# STM32H563 register map
File version: 0.4
CPU: CM33 r0p0, little endian, MPU, FPU, 4 interrupt priority bits
Registers are 32-bit, read-write, reset 0x0 unless marked. A register's access mark holds for its fields unless they carry their own. Offsets are from the block's base; [hi:lo] are bit positions; lines under a group give offsets from that group; {n}, {i} and the like mark numbered series; 'fields as' and 'values as' point back to an identical list.

## FLASH — FLASH address block description
Base 0x40022000
Same registers: SEC_FLASH 0x50022000
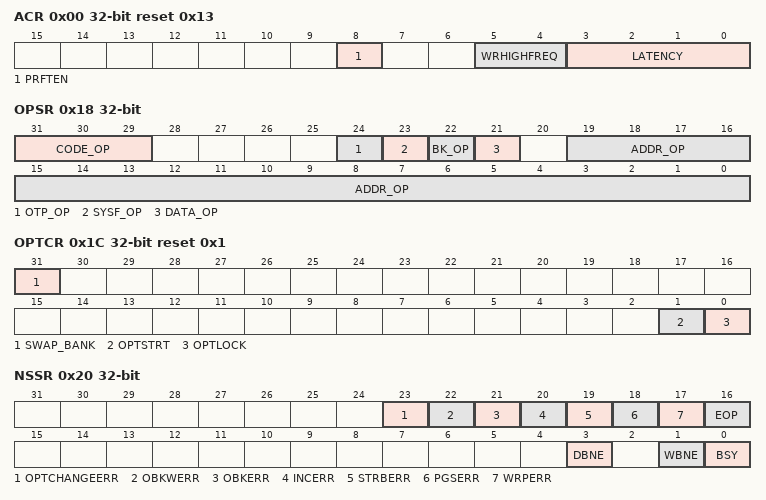
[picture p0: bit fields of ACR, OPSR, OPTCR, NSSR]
0x00 ACR reset 0x13 — FLASH access control register
  [8] PRFTEN — Prefetch enable. When bit value is modified, user must read back ACR register to be sure PRFTEN has been taken into account. Bits used to control the prefetch.
  [5:4] WRHIGHFREQ — Flash signal delay These bits are used to control the delay between nonvolatile memory signals during programming operations. Application software has to program them to the correct value depending on the embedded flash memory interface frequency. Please refer to Table�44 for details. Note: No check is performed to verify that the configuration is correct. Note: Two WRHIGHFREQ values can be selected for some frequencies.
  [3:0] LATENCY — Read latency These bits are used to control the number of wait states used during read operations on both nonvolatile memory banks. The application software has to program them to the correct value depending on the embedded flash memory interface frequency and voltage conditions. ... Note: No check is performed by hardware to verify that the configuration is correct.
0x04 NSKEYR wo — FLASH non-secure key register
  [31:0] NSKEY — Non-volatile memory non-secure configuration access unlock key
0x08 SECKEYR wo — FLASH secure key register
  [31:0] SECKEY — Non-volatile memory secure configuration access unlock key
0x0C OPTKEYR wo — FLASH option key register
  [31:0] OPTKEY — FLASH option bytes control access unlock key
0x10 NSOBKKEYR wo — FLASH non-secure OBK key register
  [31:0] NSOBKKEY — FLASH non-secure option bytes keys control access unlock key
0x14 SECOBKKEYR wo — FLASH secure OBK key register
  [31:0] SECOBKKEY — FLASH secure option bytes keys control access unlock key
0x18 OPSR ro reset not defined — FLASH operation status register
  [31:29] CODE_OP — Flash memory operation code
  [24] OTP_OP — OTP operation interrupted Indicates that reset interrupted an ongoing operation in OTP area (or OBKeys area).
  [23] SYSF_OP — Operation in system flash memory interrupted Indicates that reset interrupted an ongoing operation in system flash.
  [22] BK_OP — Interrupted operation bank It indicates which bank was concerned by operation.
  [21] DATA_OP — Flash high-cycle data area operation interrupted It indicates if flash high-cycle data area is concerned by operation.
  [19:0] ADDR_OP — Interrupted operation address
0x1C OPTCR access per field reset 0x1 (reset mask 0xFFFFFFF) — FLASH option control register
  [31] SWAP_BANK ro — Bank swapping option configuration bit SWAP_BANK controls whether Bank1 and Bank2 are swapped or not. This bit is loaded with the SWAP_BANK bit of FLASH_OPTSR_CUR register only after reset or POR.
  [1] OPTSTRT rw — Option byte start change option configuration bit OPTSTRT triggers an option byte change operation. The user can set OPTSTRT only when the OPTLOCK bit is cleared to 0. It is set only by Software and cleared when the option byte change is completed or an error occurs (PGSERR or OPTCHANGEERR). It is reseted at the same time as BSY bit. The user application cannot modify any FLASH_XXX_PRG flash interface register until the option change operation has been completed. Before setting this bit, the user has to write the required values in the FLASH_XXX_PRG registers. The FLASH_XXX_PRG registers are locked until the option byte change operation has been executed in nonvolatile memory.
  [0] OPTLOCK rw — FLASH_OPTCR lock option configuration bit The OPTLOCK bit locks the FLASH_OPTCR register as well as all _PRG registers. The correct write sequence to FLASH_OPTKEYR register unlocks this bit. If a wrong sequence is executed, or the unlock sequence to FLASH_OPTKEYR is performed twice, this bit remains locked until next system reset. It is possible to set OPTLOCK by programming it to 1. When set to 1, a new unlock sequence is mandatory to unlock it. When OPTLOCK changes from 0 to 1, the others bits of FLASH_OPTCR register do not change.
0x20 NSSR ro (reset mask 0xFFFFFFF0) — FLASH non-secure status register
  [23] OPTCHANGEERR — Option byte change error flag OPTCHANGEERR flag indicates that an error occurred during an option byte change operation. When OPTCHANGEERR is set to 1, the option byte change operation did not successfully complete. An interrupt is generated when this flag is raised if the OPTCHANGEERRIE bit of FLASH_NSCR register is set to 1. Writing 1 to CLR_OPTCHANGEERR of register FLASH_NSCCR clears OPTCHANGEERR. Note: The OPTSTRT bit in FLASH_OPTCR cannot be set while OPTCHANGEERR is set.
  [22] OBKWERR — OBK write error flag OBKWERR flag is raised when the address is not virgin on a write access to the OBK storage. Alternatively also when the OBK selector in the alternate sector is not virgin during a swap operation.
  [21] OBKERR — OBK general error flag OBKERR flag is raised when the OBK-HDPL signal from the SBS does not match the HDPL value associated with the key slot during access to the key location. Alternatively also when the ALT_SECT is unexpectedly changed while the write buffer is being filled.
  [20] INCERR — inconsistency error flag NSINCERR flag is raised when a inconsistency error occurs. An interrupt is generated if INCERRIE is set to 1. Writing 1 to CLR_INCERR bit in the FLASH_NSCCR register clears NSINCERR.
  [19] STRBERR — strobe error flag STRBERR flag is raised when a strobe error occurs (when the master attempts to write several times the same byte in the write buffer). An interrupt is generated if the STRBERRIE bit is set to 1. Writing 1 to CLR_STRBERR bit in FLASH_NSCCR register clears STRBERR.
  [18] PGSERR — programming sequence error flag PGSERR flag is raised when a sequence error occurs. An interrupt is generated if the PGSERRIE bit is set to 1. Writing 1 to CLR_PGSERR bit in FLASH_NSCCR register clears PGSERR.
  [17] WRPERR — write protection error flag WRPERR flag is raised when a protection error occurs during a program operation. An interrupt is also generated if the WRPERRIE is set to 1. Writing 1 to CLR_WRPERR bit in FLASH_NSCCR register clears WRPERR.
  [16] EOP — end of operation flag EOP flag is set when a operation (program/erase) completes. An interrupt is generated if the EOPIE is set to 1. It is not necessary to reset EOP before starting a new operation. EOP bit is cleared by writing 1 to CLR_EOP bit in FLASH_NSCCR register.
  [3] DBNE — data buffer not empty flag DBNE flag is set when the flash interface is processing 6-bits ECC data in dedicated buffer. This bit cannot be set to 0 by software. The hardware resets it once the buffer is free.
  [1] WBNE — write buffer not empty flag WBNE flag is set when the flash interface is waiting for new data to complete the write buffer. In this state, the write buffer is not empty. WBNE is reset by hardware each time the write buffer is complete or the write buffer is emptied following one of the event below: the application software forces the write operation using FW bit in FLASH_NSCR the embedded flash memory detects an error that involves data loss This bit cannot be reset by software writing 0 directly. To reset it, clear the write buffer by performing any of the above listed actions, or send the missing data.
  [0] BSY — busy flag BSY flag indicates that a flash memory is busy by an operation (write, erase, option byte change, OBK operation). It is set at the beginning of a flash memory operation and cleared when the operation finishes, or an error occurs.
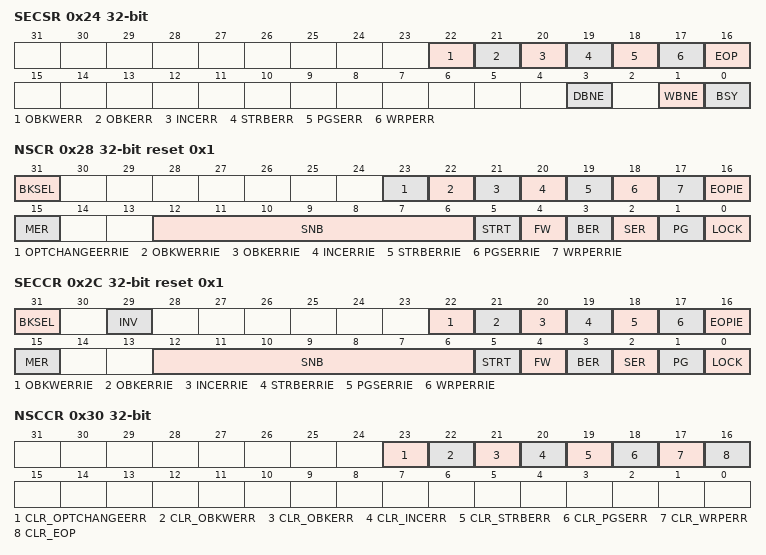
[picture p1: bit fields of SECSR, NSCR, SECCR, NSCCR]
0x24 SECSR ro (reset mask 0xFFFFFFF0) — FLASH secure status register
  [22] OBKWERR — OBK write error flag OBKWERR flag is raised when the address is not virgin on a write access to the OBK storage. Alternatively also when the OBK selector in the alternate sector is not virgin during a swap operation.
  [21] OBKERR — OBK general error flag OBKERR flag is raised when the OBK-HDPL signal from the SBS does not match the HDPL value associated with the key slot during access to the key location. Alternatively also when the ALT_SECT is unexpectedly changed while the write buffer is being filled.
  [20] INCERR — inconsistency error flag INCERR flag is raised when a inconsistency error occurs. An interrupt is generated if INCERRIE is set to 1. Writing 1 to CLR_INCERR bit in the FLASH_SECCCR register clears INCERR.
  [19] STRBERR — strobe error flag STRBERR flag is raised when a strobe error occurs (when the master attempts to write several times the same byte in the write buffer). An interrupt is generated if the STRBERRIE bit is set to 1. Writing 1 to CLR_STRBERR bit in FLASH_SECCCR register clears STRBERR.
  [18] PGSERR — programming sequence error flag PGSERR flag is raised when a sequence error occurs. An interrupt is generated if the PGSERRIE bit is set to 1. Writing 1 to CLR_PGSERR bit in FLASH_SECCCR register clears PGSERR.
  [17] WRPERR — write protection error flag WRPERR flag is raised when a protection error occurs during a program operation. An interrupt is also generated if the WRPERRIE is set to 1. Writing 1 to CLR_WRPERR bit in FLASH_SECCCR register clears WRPERR.
  [16] EOP — end of operation flag EOP flag is set when a operation (program/erase) completes. An interrupt is generated if the EOPIE is set to. It is not necessary to reset EOP before starting a new operation. EOP bit is cleared by writing 1 to CLR_EOP bit in FLASH_SECCCR register.
  [3] DBNE — data buffer not empty flag DBNE flag is set when the embedded flash memory interface is processing 6-bits ECC data in dedicated buffer. This bit cannot be set to 0 by software. The hardware resets it once the buffer is free.
  [1] WBNE — write buffer not empty flag WBNE flag is set when the flash interface is waiting for new data to complete the write buffer. In this state, the write buffer is not empty. WBNE is reset by hardware each time the write buffer is complete or the write buffer is emptied following one of the event below: the application software forces the write operation using FW bit in FLASH_SECCR the flash interface detects an error that involves data loss This bit cannot be reset by writing 0 directly by software. To reset it, clear the write buffer by performing any of the above listed actions, or send the missing data.
  [0] BSY — busy flag BSY flag indicates that a FLASH memory is busy (write, erase, option byte change, OBK operations). It is set at the beginning of a flash memory operation and cleared when the operation finishes or an error occurs.
0x28 NSCR reset 0x1 — FLASH non-secure control register
  [31] BKSEL — Bank selector bit BKSEL can only be programmed when LOCK is cleared to 0. The bit selects physical bank, SWAP_BANK setting is ignored.
  [23] OPTCHANGEERRIE — Option byte change error interrupt enable bit This bit controls if an interrupt must be generated when an error occurs during an option byte change. It can be programmed only when LOCK bit is cleared to 0.
  [22] OBKWERRIE — OBK write error interrupt enable bit OBKWERRIE enables generation of interrupt in case of OBK specific write error. This bit can be programmed only when LOCK bit is cleared to 0.
  [21] OBKERRIE — OBK general error interrupt enable bit OBKERRIE enables generating an interrupt in case of OBK specific access error. This bit can be programmed only when LOCK bit is cleared to 0.
  [20] INCERRIE — inconsistency error interrupt enable bit When INCERRIE bit is set to 1, an interrupt is generated when an inconsistency error occurs during a write operation. INCERRIE can be programmed only when LOCK is cleared to 0.
  [19] STRBERRIE — strobe error interrupt enable bit When STRBERRIE bit is set to 1, an interrupt is generated when a strobe error occurs (the master programs several times the same byte in the write buffer) during a write operation. STRBERRIE can be programmed only when LOCK is cleared to 0.
  [18] PGSERRIE — programming sequence error interrupt enable bit When this bit is set to 1, an interrupt is generated when a sequence error occurs during a program operation. PGSERRIE can be programmed only when LOCK is cleared to 0.
  [17] WRPERRIE — write protection error interrupt enable bit When this bit is set to 1, an interrupt is generated when a protection error occurs during a program operation. WRPERRIE can be programmed only when LOCK is cleared to 0.
  [16] EOPIE — end of operation interrupt control bit Setting EOPIE bit to 1 enables the generation of an interrupt at the end of a program or erase operation. EOPIE can be programmed only when LOCK is cleared to 0.
  [15] MER — Mass erase request Setting MER bit to 1 requests a mass erase operation (user flash memory only). MER can be programmed only when LOCK is cleared to 0. If BER or SER are both set, a PGSERR is raised. Error is triggered when a mass erase is required and some sectors are protected.
  [12:6] SNB — sector erase selection number These bits are used to select the target sector for an erase operation (they are unused otherwise). SNB can be programmed only when LOCK is cleared to 0. ..
  [5] STRT — erase start control bit STRT bit is used to start a sector erase or a bank erase operation. STRT can be programmed only when LOCK is cleared to 0. STRT is reset at the end of the operation or when an error occurs. It cannot be reseted by software.
  [4] FW — write forcing control bit FW forces a write operation even if the write buffer is not full. In this case all bits not written are set to 1 by hardware. FW can be programmed only when LOCK is cleared to 0. The embedded flash memory resets FW when the corresponding operation has been acknowledged. Note: Using a force-write operation prevents the application from updating later the missing bits with something else than 1, because it is likely that it leads to permanent ECC error. Write forcing is effective only if the write buffer is not empty and was filled by non-secure access (in particular, FW does not start several write operations when the force-write operations are performed consecutively). Since there is just one write buffer, FW can force a write in bank1 or bank2.
  [3] BER — erase request Setting BER bit to 1 requests a bank erase operation (user flash memory only). BER can be programmed only when LOCK is cleared to 0. If MER and SER are also set, a PGSERR is raised. Note: Write protection error is triggered when a bank erase is required and some sectors are protected.
  [2] SER — sector erase request Setting SER bit to 1 requests a sector erase. SER can be programmed only when LOCK is cleared to 0. If MER and SER are also set, a PGSERR is raised.
  [1] PG — programming control bit PG can be programmed only when LOCK is cleared to 0. PG allows programming in Bank1 and Bank2.
  [0] LOCK — configuration lock bit This bit locks the FLASH_NSCR register. The correct write sequence to FLASH_NSKEYR register unlocks this bit. If a wrong sequence is executed, or if the unlock sequence to FLASH_NSKEYR is performed twice, this bit remains locked until the next system reset. LOCK can be set by programming it to 1. When set to 1, a new unlock sequence is mandatory to unlock it. When LOCK changes from 0 to 1, the other bits of FLASH_NSCR register do not change.
0x2C SECCR reset 0x1 — FLASH secure control register
  [31] BKSEL — bank selector bit BKSEL can only be programmed when LOCK is cleared to 0. The bit selects physical bank, SWAP_BANK setting is ignored.
  [29] INV — Flash memory security state invert. This bit inverts the flash memory security state.
  [22] OBKWERRIE — OBK write error interrupt enable bit OBKWERRIE enables generation of interrupt in case of OBK specific write error. OBKWERRIE can be programmed only when LOCK is cleared to 0.
  [21] OBKERRIE — OBK general error interrupt enable bit OBKERRIE enables generating an interrupt in case of OBK specific access error. OBKERRIE can be programmed only when LOCK is cleared to 0.
  [20] INCERRIE — inconsistency error interrupt enable bit When INCERRIE bit is set to 1, an interrupt is generated when an inconsistency error occurs during a write operation. INCERRIE can be programmed only when LOCK is cleared to 0.
  [19] STRBERRIE — strobe error interrupt enable bit When STRBERRIE bit is set to 1, an interrupt is generated when a strobe error occurs (the master programs several times the same byte in the write buffer) during a write operation. STRBERRIE can be programmed only when LOCK is cleared to 0.
  [18] PGSERRIE — programming sequence error interrupt enable bit When PGSERRIE bit is set to 1, an interrupt is generated when a sequence error occurs during a program operation. PGSERRIE can be programmed only when LOCK is cleared to 0.
  [17] WRPERRIE — write protection error interrupt enable bit When WRPERRIE bit is set to 1, an interrupt is generated when a protection error occurs during a program operation. WRPERRIE can be programmed only when LOCK is cleared to 0.
  [16] EOPIE — end of operation interrupt control bit Setting EOPIE bit to 1 enables the generation of an interrupt at the end of a program/erase operation. EOPIE can be programmed only when LOCK is cleared to 0.
  [15] MER — mass erase request Setting MER bit to 1 requests a mass erase operation (user flash memory only). MER can be programmed only when LOCK is cleared to 0. If BER or SER are also set, a PGSERR is raised. Error is triggered when a mass erase is required and some sectors are protected.
  [12:6] SNB — sector erase selection number These bits are used to select the target sector for an erase operation (they are unused otherwise). SNB can be programmed only when LOCK is cleared to 0. ..
  [5] STRT — erase start control bit STRT bit is used to start a sector erase or a bank erase operation. STRT can be programmed only when LOCK is cleared to 0. STRT is reseted at the end of the operation or when an error occurs. It cannot be reset by software.
  [4] FW — write forcing control bit FW forces a write operation even if the write buffer is not full. In this case all bits not written are set to 1 by hardware. FW can be programmed only when LOCK is cleared to 0. The embedded flash memory resets FW when the corresponding operation has been acknowledged. Note: Using a force-write operation prevents the application from updating later the missing bits with something else than 1, because it is likely that it leads to permanent ECC error. Write forcing is effective only if the write buffer is not empty and was filled by secure access (in particular, FW does not start several write operations when the force-write operations are performed consecutively). Since there is just one write buffer, FW can force a write in bank1 or bank2.
  [3] BER — erase request Setting BER bit to 1 requests a bank erase operation (user flash memory only). BER can be programmed only when LOCK is cleared to 0. If MER and SER are also set, a PGSERR is raised. Note: Write protection error is triggered when a bank erase is required and some sectors are protected.
  [2] SER — sector erase request Setting SER bit to 1 requests a sector erase. SER can be programmed only when LOCK is cleared to 0. If BER and MER are also set, a PGSERR is raised.
  [1] PG — programming control bit PG can be programmed only when LOCK is cleared to 0. PG allows programming in Bank1 and Bank2.
  [0] LOCK — configuration lock bit This bit locks the FLASH_SECCR register. The correct write sequence to FLASH_SECKEYR register unlocks this bit. If a wrong sequence is executed, or if the unlock sequence to FLASH_NSKEYR is performed twice, this bit remains locked until the next system reset. LOCK can be set by programming it to 1. When set to 1, a new unlock sequence is mandatory to unlock it. When LOCK changes from 0 to 1, the other bits of FLASH_SECCR register do not change.
0x30 NSCCR wo — FLASH non-secure clear control register
  [23] CLR_OPTCHANGEERR — Clear the flag corresponding flag in FLASH_NSSR by writing this bit.
  [22] CLR_OBKWERR — OBKWERR flag clear bit. Setting this bit to 1 resets to 0 OBKWERR flag in FLASH_NSSR register.
  [21] CLR_OBKERR — OBKERR flag clear bit. Setting this bit to 1 resets to 0 OBKERR flag in FLASH_NSSR register.
  [20] CLR_INCERR — INCERR flag clear bit Setting this bit to 1 resets to 0 INCERR flag in FLASH_NSSR register.
  [19] CLR_STRBERR — STRBERR flag clear bit Setting this bit to 1 resets to 0 STRBERR flag in FLASH_NSSR register.
  [18] CLR_PGSERR — PGSERR flag clear bit Setting this bit to 1 resets to 0 PGSERR flag in FLASH_NSSR register.
  [17] CLR_WRPERR — WRPERR flag clear bit Setting this bit to 1 resets to 0 WRPERR flag in FLASH_NSSR register.
  [16] CLR_EOP — EOP flag clear bit Setting this bit to 1 resets to 0 EOP flag in FLASH_NSSR register.
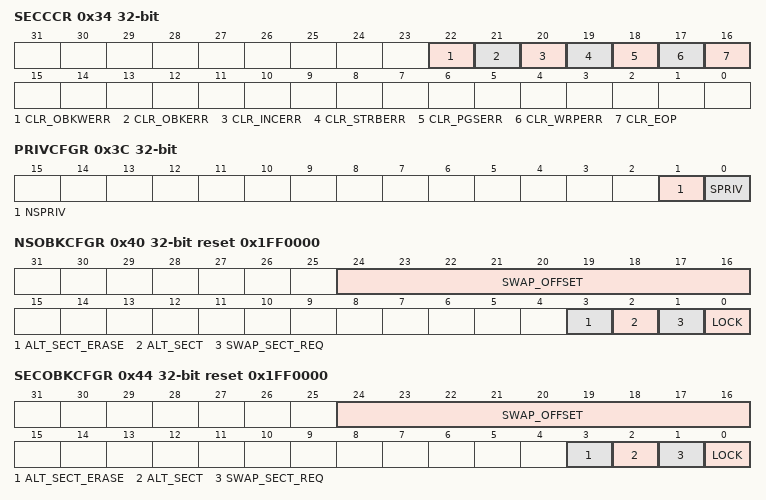
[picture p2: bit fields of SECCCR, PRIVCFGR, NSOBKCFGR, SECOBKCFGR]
0x34 SECCCR wo — FLASH secure clear control register
  [22] CLR_OBKWERR — OBKWERR flag clear bit Setting this bit to 1 resets to 0 OBKWERR flag in FLASH_SECSR register.
  [21] CLR_OBKERR — OBKWERR flag clear bit Setting this bit to 1 resets to 0 OBKWERR flag in FLASH_SECSR register.
  [20] CLR_INCERR — INCERR flag clear bit Setting this bit to 1 resets to 0 INCERR flag in FLASH_SECSR register.
  [19] CLR_STRBERR — STRBERR flag clear bit Setting this bit to 1 resets to 0 STRBERR flag in FLASH_SECSR register.
  [18] CLR_PGSERR — PGSERR flag clear bit Setting this bit to 1 resets to 0 PGSERR flag in FLASH_SECSR register.
  [17] CLR_WRPERR — WRPERR flag clear bit Setting this bit to 1 resets to 0 WRPERR flag in FLASH_SECSR register.
  [16] CLR_EOP — EOP flag clear bit Setting this bit to 1 resets to 0 EOP flag in FLASH_SECSR register.
0x3C PRIVCFGR — FLASH privilege configuration register
  [1] NSPRIV — privilege attribute for non secure registers
  [0] SPRIV — privilege attribute for secure registers
0x40 NSOBKCFGR reset 0x1FF0000 — FLASH non-secure OBK configuration register
  [24:16] SWAP_OFFSET — Key index (offset /16 bits) pointing for next swap. 0x01 means that only the first OBK data (128 bits) is copied from current to alternate OBK sector 0x02 means that the two first OBK data is copied … …
  [3] ALT_SECT_ERASE — alternate sector erase bit When ALT_SECT bit is set, use this bit to generate an erase command for the OBK alternate sector. It is set only by Software and cleared when the OBK swap operation is completed or an error occurs (PGSERR). It is reseted at the same time as BUSY bit.
  [2] ALT_SECT — alternate sector bit This bit must not change while filling the write buffer, otherwise an error (OBKERR) is generated
  [1] SWAP_SECT_REQ — OBK swap sector request bit When set, all the OBKs which have not been updated in the alternate sector is copied from current sector to alternate one. The SWAP_OFFSET value must be a certain minimum value in order for the swap to be launched in OBK-HDPL ≠ 0. Minimum value is 16 for OBK-HDPL = 1, 144 for OBK-HDPL = 2 and 192 for OBK-HDPL = 3.
  [0] LOCK — OBKCFGR lock option configuration bit This bit locks the FLASH_NSOBKCFGR register. The correct write sequence to FLASH_NSOBKKEYR register unlocks this bit. If a wrong sequence is executed, or if the unlock sequence to FLASH_NSOBKKEYR is performed twice, this bit remains locked until the next system reset. LOCK can be set by programming it to 1. When set to 1, a new unlock sequence is mandatory to unlock it. When LOCK changes from 0 to 1, the other bits of FLASH_NSCR register do not change.
0x44 SECOBKCFGR reset 0x1FF0000 — FLASH secure OBK configuration register
  [24:16] SWAP_OFFSET — key index (offset /16 bits) pointing for next swap. …
  [3] ALT_SECT_ERASE — alternate sector erase bit When ALT_SECT bit is set, use this bit to generate an erase command for the OBK alternate sector. It is set only by Software and cleared when the OBK swap operation is completed or an error occurs (PGSERR). It is reseted at the same time as the BUSY bit.
  [2] ALT_SECT — alternate sector bit This bit must not change while filling the write buffer, otherwise an error is generated
  [1] SWAP_SECT_REQ — OBK swap sector request bit When set, all the OBKs which have not been updated in the alternate sector is copied from current sector to alternate one. The SWAP_OFFSET value must be a certain minimum value in order for the swap to be launched in OBK-HDPL ≠ 0. Minimum value is 16 for OBK-HDPL = 1, 144 for OBK-HDPL = 2 and 192 for OBK-HDPL = 3.
  [0] LOCK — OBKCFGR lock option configuration bit This bit locks the FLASH_OBKCFGR register. The correct write sequence to FLASH_SECOBKKEYR register unlocks this bit. If a wrong sequence is executed, or if the unlock sequence to FLASH_SECOBKKEYR is performed twice, this bit remains locked until the next system reset. LOCK can be set by programming it to 1. When set to 1, a new unlock sequence is mandatory to unlock it. When LOCK changes from 0 to 1, the other bits of FLASH_NSCR register do not change.
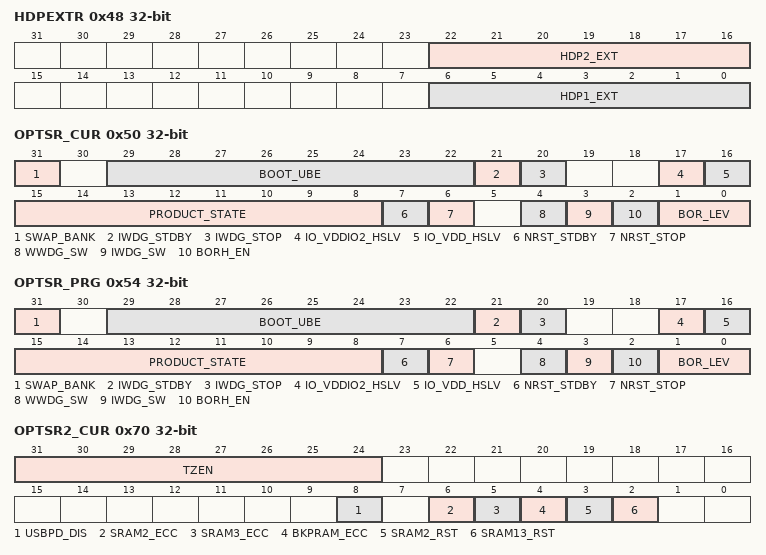
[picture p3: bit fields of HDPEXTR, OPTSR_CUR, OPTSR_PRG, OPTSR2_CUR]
0x48 HDPEXTR — FLASH HDP extension register
  [22:16] HDP2_EXT — HDP area extension in 8�Kbytes sectors in bank 2. Extension is added after the HDP2_END sector (included).
  [6:0] HDP1_EXT — HDP area extension in 8�Kbytes sectors in Bank1. Extension is added after the HDP1_END sector (included).
0x50 OPTSR_CUR ro reset not defined — FLASH option status register
  [31] SWAP_BANK — Bank swapping option status bit SWAP_BANK reflects whether Bank1 and Bank2 are swapped or not. SWAP_BANK is loaded to SWAP_BANK of FLASH_OPTCR after a reset.
  [29:22] BOOT_UBE — Available only on cryptography enabled devices. Unique boot entry control, selects either ST or OEM iRoT for secure boot.
  [21] IWDG_STDBY — IWDG Standby mode freeze option status bit When set the independent watchdog IWDG is frozen in system Standby mode.
  [20] IWDG_STOP — IWDG Stop mode freeze option status bit When set the independent watchdog IWDG is in system Stop mode.
  [17] IO_VDDIO2_HSLV — High-speed IO at low V<sub>DDIO2</sub> voltage configuration bit. This bit can be set only with V<sub>DDIO2</sub> below 2.7�V.
  [16] IO_VDD_HSLV — High-speed IO at low V<sub>DD</sub> voltage configuration bit. This bit can be set only with V<sub>DD</sub> below 2.7�V.
  [15:8] PRODUCT_STATE — Life state code (based on Hamming 8,4). More information in Section�7.6.11: Product state transitions.
  [7] NRST_STDBY — Core domain Standby entry reset option status bit
  [6] NRST_STOP — Core domain Stop entry reset option status bit
  [4] WWDG_SW — WWDG control mode option status bit
  [3] IWDG_SW — IWDG control mode option status bit
  [2] BORH_EN — Brownout high enable
  [1:0] BOR_LEV — Brownout level option status bit These bits reflects the power level that generates a system reset. 00 or 11: BOR Level 1, the threshold level is low (around 2.1�V)
0x54 OPTSR_PRG reset not defined — FLASH option status register
  [31] SWAP_BANK — Bank swapping option configuration bit SWAP_BANK option bit is used to configure whether the Bank1 and Bank2 are swapped or not. This bit is loaded with the SWAP_BANK bit of FLASH_OPTSR_CUR register after a reset.
  [29:22] BOOT_UBE — Available only on cryptography enabled devices. Unique boot entry control, selects either ST or OEM iRoT for secure boot. In Open PRODUCT_STATE this value selects bootloader. Defaut value.
  [21] IWDG_STDBY — IWDG Standby mode freeze option status bit When set the independent watchdog IWDG is frozen in system Standby mode.
  [20] IWDG_STOP — IWDG Stop mode freeze option status bit When set the independent watchdog IWDG is in system Stop mode.
  [17] IO_VDDIO2_HSLV — High-speed IO at low VDDIO2 voltage configuration bit. This bit can be set only with VDDIO2 below 2.7�V.
  [16] IO_VDD_HSLV — High-speed IO at low VDD voltage configuration bit. This bit can be set only with VDD below 2.7�V.
  [15:8] PRODUCT_STATE — Life state code (based on Hamming 8,4). More information in Section�7.6.11: Product state transitions.
  [7] NRST_STDBY — Core domain Standby entry reset option configuration bit
  [6] NRST_STOP — Core domain Stop entry reset option configuration bit
  [4] WWDG_SW — WWDG control mode option configuration bit
  [3] IWDG_SW — IWDG control mode option configuration bit
  [2] BORH_EN — Brownout high enable configuration bit
  [1:0] BOR_LEV — Brownout level option configuration bit These bits reflects the power level that generates a system reset. 00 or 11: BOR Level 1, the threshold level is low (around 2.1 V)
0x60 NSEPOCHR_CUR ro reset not defined — FLASH non-secure EPOCH register
  [23:0] NS_EPOCH — Non-volatile non-secure EPOCH counter
0x68 SECEPOCHR_CUR ro reset not defined — FLASH secure EPOCH register
  [23:0] SEC_EPOCH — Non-volatile secure EPOCH counter
0x70 OPTSR2_CUR ro reset not defined — FLASH option status register 2
  [31:24] TZEN — TrustZone enable configuration bits This bit enables the device is in TrustZone mode during an option byte change.
  [8] USBPD_DIS — USB power delivery configuration option bit
  [6] SRAM2_ECC — SRAM2 ECC detection and correction disable
  [5] SRAM3_ECC — SRAM3 ECC detection and correction disable
  [4] BKPRAM_ECC — Backup RAM ECC detection and correction disable
  [3] SRAM2_RST — SRAM2 erase when system reset
  [2] SRAM13_RST — SRAM1 and SRAM3 erase upon system reset
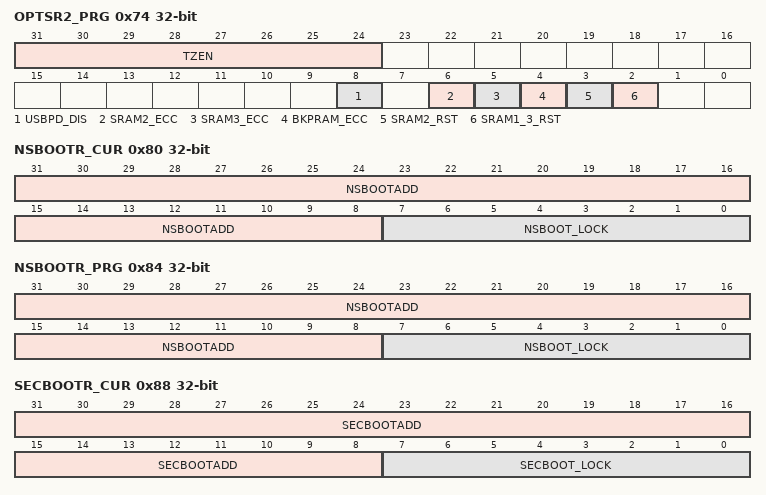
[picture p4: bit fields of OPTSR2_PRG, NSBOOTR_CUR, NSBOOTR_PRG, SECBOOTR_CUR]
0x74 OPTSR2_PRG reset not defined — FLASH option status register 2
  [31:24] TZEN — TrustZone enable configuration bits This bit enables the device is in TrustZone mode during an option byte change.
  [8] USBPD_DIS — USB power delivery configuration option bit
  [6] SRAM2_ECC — SRAM2 ECC detection and correction disable
  [5] SRAM3_ECC — SRAM3 ECC detection and correction disable
  [4] BKPRAM_ECC — Backup RAM ECC detection and correction disable
  [3] SRAM2_RST — SRAM2 erase when system reset Note: SRAM erase is triggered by option byte change operation, when enabling this feature.
  [2] SRAM1_3_RST — SRAM1 and SRAM3 erase upon system reset Note: SRAM erase is triggered by option byte change operation, when enabling this feature.
0x80 NSBOOTR_CUR ro reset not defined — FLASH non-secure boot register
  [31:8] NSBOOTADD — Non secure unique boot entry address These bits reflect the Non secure UBE address
  [7:0] NSBOOT_LOCK — A field locking the values of SWAP_BANK, and NSBOOTADD settings.
0x84 NSBOOTR_PRG reset not defined — FLASH non-secure boot register
  [31:8] NSBOOTADD — Non secure unique boot entry address These bits allow configuring the Non secure BOOT address
  [7:0] NSBOOT_LOCK — A field locking the values of SWAP_ BANK, and NSBOOTADD settings.
0x88 SECBOOTR_CUR ro reset not defined — FLASH secure boot register
  [31:8] SECBOOTADD — Unique boot entry secure address These bits reflect the Secure UBE address
  [7:0] SECBOOT_LOCK — A field locking the values of UBE, SWAP_BANK, and SECBOOTADD settings.
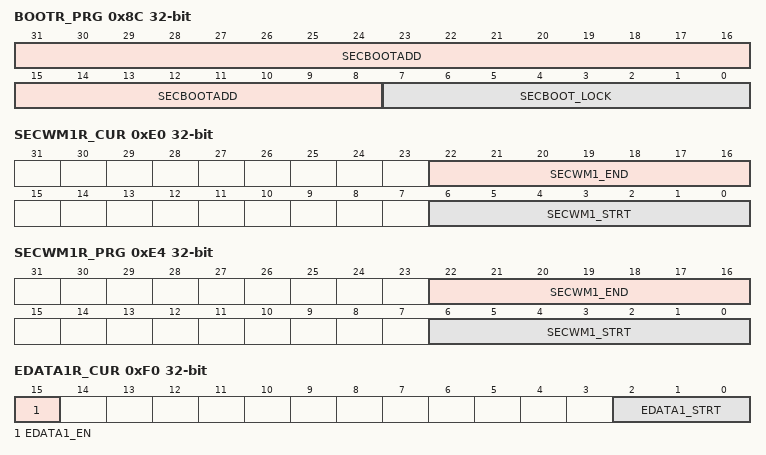
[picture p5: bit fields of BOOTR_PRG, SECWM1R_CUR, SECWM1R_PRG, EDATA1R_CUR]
0x8C BOOTR_PRG reset not defined — FLASH secure boot register
  [31:8] SECBOOTADD — Secure unique boot entry address. These bits allow configuring the secure UBE address.
  [7:0] SECBOOT_LOCK — A field locking the values of UBE, SWAP_ BANK, and SECBOOTADD setting.
0x90 OTPBLR_CUR ro reset not defined — FLASH non-secure OTP block lock
  [31:0] LOCKBL — OTP block lock Block n corresponds to OTP 16-bit word 32 x n to 32 x n + 31. LOCKBL[n] = 1 indicates that all OTP 16-bit words in OTP Block n are locked and attempt to program them results in WRPERR. LOCKBL[n] = 0 indicates that all OTP 16-bit words in OTP Block n are not locked. When one block is locked, it’s not possible to remove the write protection. Also if not locked, it is not possible to erase OTP words.
0x94 OTPBLR_PRG reset not defined — FLASH non-secure OTP block lock
  [31:0] LOCKBL — OTP block lock Block n corresponds to OTP 16-bit word 32 x n to 32 x n + 31. LOCKBL[n] = 1 indicates that all OTP 16-bit words in OTP Block n are locked and attempt to program them results in WRPERR. LOCKBL[n] = 0 indicates that all OTP 16-bit words in OTP Block n are not locked. When one block is locked, it is not possible to remove the write protection. LOCKBL bits can be set if the corresponding bit in FLASH_OTPBLR_CUR is cleared.
{0x9C+4i} SECBB1R{i} (i=1..4) — FLASH secure block based register for Bank 1
  [31:0] SECBB1 — Secure/non-secure 8�Kbytes flash Bank 1 sector attributes
{0xBC+4i} PRIVBB1R{i} (i=1..4) — FLASH privilege block based register for Bank 1
  [31:0] PRIVBB1 — Privileged/unprivileged 8-Kbyte flash Bank 1 sector attribute
0xE0 SECWM1R_CUR ro (reset mask 0xFF00FF00) — FLASH security watermark for Bank 1
  [22:16] SECWM1_END — Bank1 security WM area 1 end sector
  [6:0] SECWM1_STRT — Bank1 security WM area 1 start sector
0xE4 SECWM1R_PRG (reset mask 0xFF00FF00) — FLASH security watermark for Bank 1
  fields as SECWM1R_CUR
0xE8 WRP1R_CUR ro reset not defined — FLASH write sector group protection for Bank 1
  [31:0] WRPSG1 — Bank 1 sector group protection option status byte Each FLASH_WRP1R_CUR bit reflects the write protection status of the corresponding group of four consecutive sectors in bank 1 (0: the group is write protected; 1: the group is not write protected) Bit 0: Group embedding sectors 0 to 3 Bit 1: Group embedding sectors 4 to 7 Bit N: Group embedding sectors 4 x N to 4 x N + 3 Bit 31: Group embedding sectors 124 to 127
0xEC WRP1R_PRG reset not defined — FLASH write sector group protection for Bank 1
  [31:0] WRPSG1 — Bank1 sector group protection option status byte Setting WRPSG1 bits to 0 write protects the corresponding group of four consecutive sectors in bank 1 (0: the group is write protected; 1: the group is not write protected) Bit 0: Group embedding sectors 0 to 3 Bit 1: Group embedding sectors 4 to 7 Bit N: Group embedding sectors 4 x N to 4 x N + 3 Bit 31: Group embedding sectors 124 to 127
0xF0 EDATA1R_CUR ro reset not defined — FLASH data sector configuration Bank 1
  [15] EDATA1_EN — Bank1 flash high-cycle data enable
  [2:0] EDATA1_STRT — EDATA1_STRT contains the start sectors of the flash high-cycle data area in Bank1 There is no hardware effect to those bits. They shall be managed by ST tools in Flasher. ...
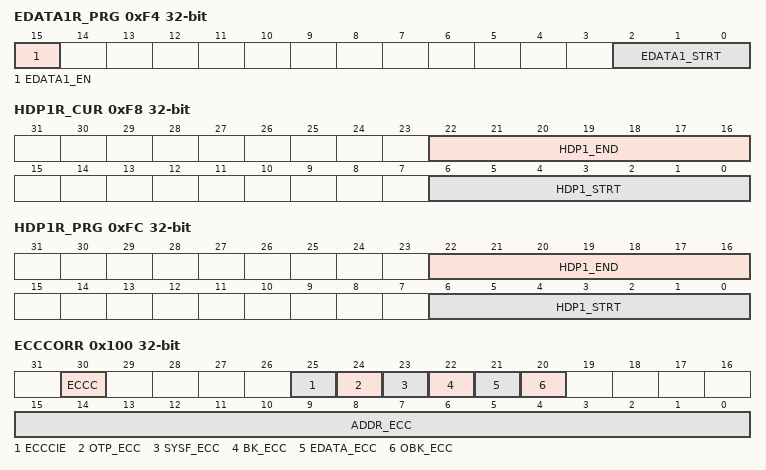
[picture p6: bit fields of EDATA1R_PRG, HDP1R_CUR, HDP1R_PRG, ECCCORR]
0xF4 EDATA1R_PRG reset not defined — FLASH data sector configuration Bank 1
  [15] EDATA1_EN — Bank 1 flash high-cycle data enable
  [2:0] EDATA1_STRT — EDATA1_STRT contains the start sectors of the flash high-cycle data area in Bank 1 There is no hardware effect to those bits. They shall be managed by ST tools in Flasher. ... Note: 111: The eight last sectors of the Bank 1 are reserved for flash high-cycle data
0xF8 HDP1R_CUR ro reset not defined — FLASH HDP Bank 1 configuration
  [22:16] HDP1_END — HDPL barrier end set in number of 8-Kbyte sectors
  [6:0] HDP1_STRT — HDPL barrier start set in number of 8-Kbyte sectors
0xFC HDP1R_PRG reset not defined — FLASH HDP Bank 1 configuration
  fields as HDP1R_CUR
0x100 ECCCORR access per field — FLASH ECC correction register
  [30] ECCC rw — ECC correction set by hardware when single ECC error has been detected and corrected. Cleared by writing 1.
  [25] ECCCIE rw — ECC single correction error interrupt enable bit When ECCCIE bit is set to 1, an interrupt is generated when an ECC single correction error occurs during a read operation.
  [24] OTP_ECC ro — OTP ECC error bit This bit is set to 1 when one single ECC correction occurred during the last successful read operation from the read-only/ OTP area. The address of the ECC error is available in ADDR_ECC bitfield.
  [23] SYSF_ECC ro — ECC fail for corrected ECC error in system flash memory It indicates if system flash memory is concerned by ECC error.
  [22] BK_ECC ro — ECC fail bank for corrected ECC error It indicates which bank is concerned by ECC error
  [21] EDATA_ECC ro — ECC fail for corrected ECC error in flash high-cycle data area It indicates if flash high-cycle data area is concerned by ECC error.
  [20] OBK_ECC ro — Single ECC error corrected in flash OB Keys storage area. It indicates the OBK storage concerned by ECC error.
  [15:0] ADDR_ECC ro — ECC error address When an ECC error occurs (for single correction) during a read operation, the ADDR_ECC contains the address that generated the error. ADDR_ECC is reset when the flag error is reset. The flash interface programs the address in this register only when no ECC error flags are set. This means that only the first address that generated an ECC error is saved. The address in ADDR_ECC is relative to the flash memory area where the error occurred (user flash memory, system flash memory, data area, read-only/OTP area).
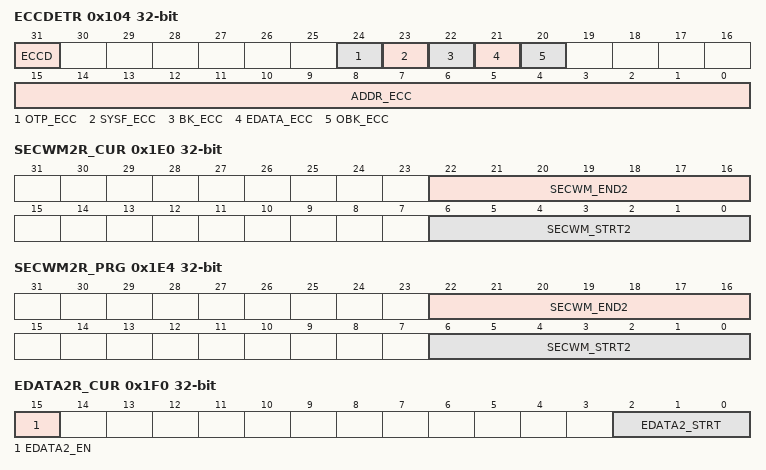
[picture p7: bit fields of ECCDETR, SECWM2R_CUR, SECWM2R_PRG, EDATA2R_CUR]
0x104 ECCDETR access per field — FLASH ECC detection register
  [31] ECCD rw — ECC detection Set by hardware when two ECC error has been detected. When this bit is set, a NMI is generated. Cleared by writing 1. Needs to be cleared in order to detect subsequent double ECC errors.
  [24] OTP_ECC ro — OTP ECC error bit This bit is set to 1 when double ECC detection occurred during the last read operation from the read-only/ OTP area. The address of the ECC error is available in ADDR_ECC bitfield.
  [23] SYSF_ECC ro — ECC fail for double ECC error in system flash memory It indicates if system flash memory is concerned by ECC error.
  [22] BK_ECC ro — ECC fail bank for double ECC error It indicates which bank is concerned by ECC error
  [21] EDATA_ECC ro — ECC fail double ECC error in flash high-cycle data area It indicates if flash high-cycle data area is concerned by ECC error.
  [20] OBK_ECC ro — ECC fail double ECC error in flash OB Keys storage area. It indicates the OBK storage concerned by ECC error.
  [15:0] ADDR_ECC ro — ECC error address When an ECC error occurs (double detection) during a read operation, the ADDR_ECC contains the address that generated the error. ADDR_ECC is reset when the flag error is reset. The flash interface programs the address in this register only when no ECC error flags are set. This means that only the first address that generated an double ECC error is saved. The address in ADDR_ECC is relative to the flash memory area where the error occurred (user flash memory, system flash memory, data area, read-only/OTP area).
0x108 ECCDR ro — FLASH ECC data
  [15:0] DATA_ECC — ECC error data When an double detection ECC error occurs on special areas with 6-bit ECC on 16-bit data (data area, read-only/OTP area), the failing data is read to this register. By checking if it is possible to determine whether the failure was on a real data, or due to access to uninitialized memory.
{0x19C+4i} SECBB2R{i} (i=1..4) — FLASH secure block-based register for Bank 2
  [31:0] SECBB2 — Secure/non-secure flash Bank 2 sector attribute
{0x1BC+4i} PRIVBB2R{i} (i=1..4) — FLASH privilege block-based register for Bank 2
  [31:0] PRIVBB2 — Privileged / non-privileged 8-Kbyte flash Bank 2 sector attribute
0x1E0 SECWM2R_CUR ro (reset mask 0xFF00FF00) — FLASH security watermark for Bank 2
  [22:16] SECWM_END2 — Bank2 security WM end sector
  [6:0] SECWM_STRT2 — Bank2 security WM area start sector
0x1E4 SECWM2R_PRG (reset mask 0xFF00FF00) — FLASH security watermark for Bank 2
  [22:16] SECWM_END2 — Bank 2 security WM area end sector
  [6:0] SECWM_STRT2 — Bank 2 security WM area start sector
0x1E8 WRP2R_CUR ro reset not defined — FLASH write sector group protection for Bank 2
  [31:0] WRPSG2 — Bank2 sector group protection option status byte Each FLASH_WRP2R_CUR bit reflects the write protection status of the corresponding group of 4 consecutive sectors in bank 2 (0: group is write protected; 1: group is not write protected) Bit 0: Group embedding sectors 0 to 3 Bit 1: Group embedding sectors 4 to 7 Bit N: Group embedding sectors 4 x N to 4 x N + 3 Bit 31: Group embedding sectors 124 to 127
0x1EC WRP2R_PRG reset not defined — FLASH write sector group protection for Bank 2
  [31:0] WRPSG2 — Bank 2 sector group protection option status byte Setting WRPSGn2 bits to 0 write protects the corresponding group of four consecutive sectors in Bank 2 (0: group is write protected; 1: group is not write protected) Bit 0: Group embedding sectors 0 to 3 Bit 1: Group embedding sectors 4 to 7 Bit N: Group embedding sectors 4 x N to 4 x N + 3 Bit 31: Group embedding sectors 124 to 127
0x1F0 EDATA2R_CUR ro reset not defined — FLASH data sectors configuration Bank 2
  [15] EDATA2_EN — Bank2 flash high-cycle data enable
  [2:0] EDATA2_STRT — EDATA2_STRT contains the start sectors of the flash high-cycle data area in Bank 2 There is no hardware effect to those bits. They shall be managed by ST tools in Flasher. ... Note: 111: The eight last sectors of the Bank 2 are reserved for flash high-cycle data
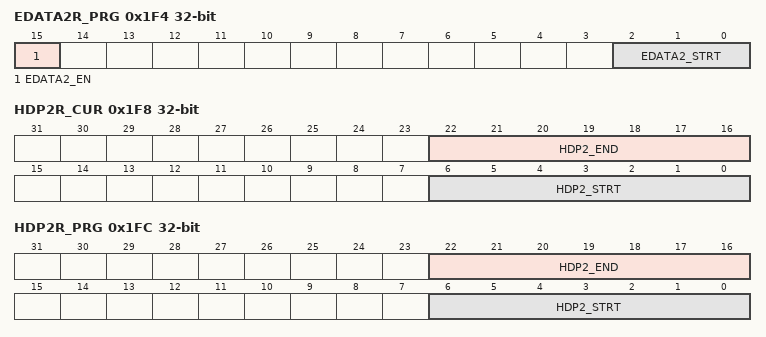
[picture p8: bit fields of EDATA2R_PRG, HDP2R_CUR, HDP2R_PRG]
0x1F4 EDATA2R_PRG reset not defined — FLASH data sector configuration Bank 2
  [15] EDATA2_EN — Bank 2 flash high-cycle data enable
  [2:0] EDATA2_STRT — EDATA2_STRT contains the start sectors of the flash high-cycle data area in Bank 2 There is no hardware effect to those bits. They shall be managed by ST tools in Flasher. ... Note: 111: The eight last sectors of the Bank 2 are reserved for flash high-cycle data.
0x1F8 HDP2R_CUR ro reset not defined — FLASH HDP Bank 2 configuration
  [22:16] HDP2_END — HDPL barrier end set in number of 8-Kbyte sectors
  [6:0] HDP2_STRT — HDPL barrier start set in number of 8-Kbyte sectors
0x1FC HDP2R_PRG reset not defined — FLASH HDP Bank 2 configuration
  fields as HDP2R_CUR
